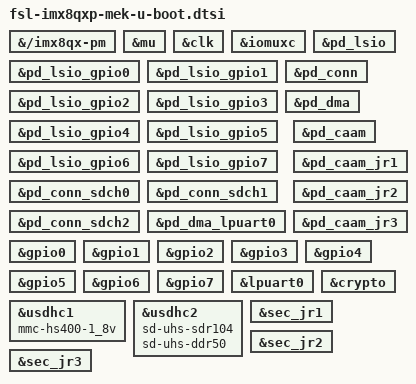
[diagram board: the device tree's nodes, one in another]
// SPDX-License-Identifier: GPL-2.0+
/*
 * Copyright 2018, 2021 NXP
 */

#include "imx8qxp-u-boot.dtsi"

&{/imx8qx-pm} {

	u-boot,dm-spl;
};

&mu {
	u-boot,dm-spl;
};

&clk {
	u-boot,dm-spl;
};

&iomuxc {
	u-boot,dm-spl;
};

&pd_lsio {
	u-boot,dm-spl;
};

&pd_lsio_gpio0 {
	u-boot,dm-spl;
};

&pd_lsio_gpio1 {
	u-boot,dm-spl;
};

&pd_lsio_gpio2 {
	u-boot,dm-spl;
};

&pd_lsio_gpio3 {
	u-boot,dm-spl;
};

&pd_lsio_gpio4 {
	u-boot,dm-spl;
};

&pd_lsio_gpio5 {
	u-boot,dm-spl;
};

&pd_lsio_gpio6 {
	u-boot,dm-spl;
};

&pd_lsio_gpio7 {
	u-boot,dm-spl;
};

&pd_conn {
	u-boot,dm-spl;
};

&pd_conn_sdch0 {
	u-boot,dm-spl;
};

&pd_conn_sdch1 {
	u-boot,dm-spl;
};

&pd_conn_sdch2 {
	u-boot,dm-spl;
};

&pd_dma {
	u-boot,dm-spl;
};

&pd_dma_lpuart0 {
	u-boot,dm-spl;
};

&pd_caam {
	u-boot,dm-spl;
};

&pd_caam_jr1 {
	u-boot,dm-spl;
};

&pd_caam_jr2 {
	u-boot,dm-spl;
};

&pd_caam_jr3 {
	u-boot,dm-spl;
};

&gpio0 {
	u-boot,dm-spl;
};

&gpio1 {
	u-boot,dm-spl;
};

&gpio2 {
	u-boot,dm-spl;
};

&gpio3 {
	u-boot,dm-spl;
};

&gpio4 {
	u-boot,dm-spl;
};

&gpio5 {
	u-boot,dm-spl;
};

&gpio6 {
	u-boot,dm-spl;
};

&gpio7 {
	u-boot,dm-spl;
};

&lpuart0 {
	u-boot,dm-spl;
};

&usdhc1 {
	u-boot,dm-spl;
	mmc-hs400-1_8v;
};

&usdhc2 {
	u-boot,dm-spl;
	sd-uhs-sdr104;
	sd-uhs-ddr50;
};

&crypto {
	u-boot,dm-spl;
};

&sec_jr1 {
	u-boot,dm-spl;
};

&sec_jr2 {
	u-boot,dm-spl;
};

&sec_jr3 {
	u-boot,dm-spl;
};
